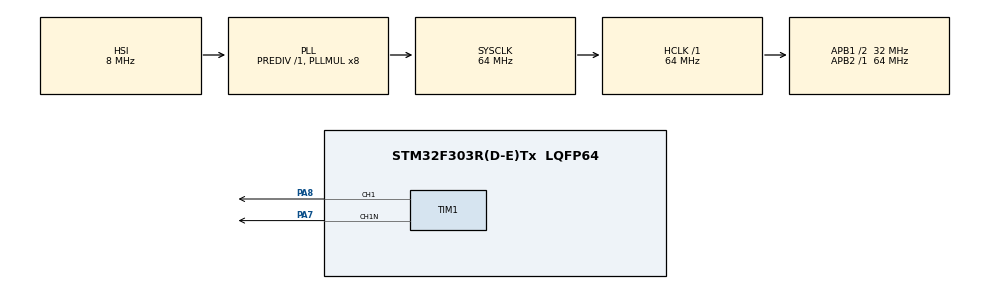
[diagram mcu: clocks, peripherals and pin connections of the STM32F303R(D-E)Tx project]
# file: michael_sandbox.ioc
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Mcu.Family=STM32F3
Mcu.Name=STM32F303R(D-E)Tx
Mcu.Package=LQFP64
NVIC.PriorityGroup=NVIC_PRIORITYGROUP_4
NVIC.TIM2_IRQn=true\:0\:0\:false\:false\:true\:true\:true
NVIC.TIM4_IRQn=true\:0\:0\:false\:false\:true\:true\:true
NVIC.TIM6_DAC_IRQn=true\:0\:0\:false\:false\:true\:true\:true
PA7.Mode=PWM Generation1 CH1 CH1N
PA7.Signal=TIM1_CH1N
PA8.Signal=S_TIM1_CH1
ProjectManager.HeapSize=0x200
ProjectManager.StackSize=0x400
ProjectManager.TargetToolchain=STM32CubeIDE
RCC.AHBFreq_Value=64000000
RCC.APB1CLKDivider=RCC_HCLK_DIV2
RCC.APB1Freq_Value=32000000
RCC.APB1TimFreq_Value=64000000
RCC.APB2Freq_Value=64000000
RCC.APB2TimFreq_Value=64000000
RCC.CortexFreq_Value=64000000
RCC.HCLKFreq_Value=64000000
RCC.HSE_VALUE=8000000
RCC.HSI_VALUE=8000000
RCC.LSE_VALUE=32768
RCC.PLLMUL=RCC_PLL_MUL8
RCC.SYSCLKFreq_VALUE=64000000
RCC.SYSCLKSourceVirtual=RCC_SYSCLKSOURCE_PLLCLK
RCC.USBFreq_Value=64000000
SH.S_TIM1_CH1.0=TIM1_CH1,PWM Generation1 CH1 CH1N
TIM1.Channel-PWM\ Generation1\ CH1\ CH1N=TIM_CHANNEL_1
TIM2.AutoReloadPreload=TIM_AUTORELOAD_PRELOAD_ENABLE
TIM2.CounterMode=TIM_COUNTERMODE_DOWN
TIM2.Period=6400
TIM4.AutoReloadPreload=TIM_AUTORELOAD_PRELOAD_ENABLE
TIM4.CounterMode=TIM_COUNTERMODE_DOWN
TIM4.Period=32000
TIM6.AutoReloadPreload=TIM_AUTORELOAD_PRELOAD_ENABLE
TIM6.Period=64
TIM6.Prescaler=10000
VP_TIM1_VS_ClockSourceINT.Mode=Internal
VP_TIM2_VS_ClockSourceINT.Mode=Internal
VP_TIM4_VS_ClockSourceINT.Mode=Internal
VP_TIM6_VS_ClockSourceINT.Mode=Enable_Timer
board=custom

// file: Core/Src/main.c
/* USER CODE BEGIN Header */
/**
  ******************************************************************************
  * @file           : main.c
  * @brief          : Main program body
  ******************************************************************************
  * @attention
  *
  * <h2><center>&copy; Copyright (c) 2019 STMicroelectronics.
  * All rights reserved.</center></h2>
  *
  * This software component is licensed by ST under BSD 3-Clause license,
  * the "License"; You may not use this file except in compliance with the
  * License. You may obtain a copy of the License at:
  *                        opensource.org/licenses/BSD-3-Clause
  *
  ******************************************************************************
  */
/* USER CODE END Header */

#include "main.h"

/* USER CODE BEGIN Includes */
#include "timer.h"
#include "gpio.h"
#include "fsm.h"

/* USER CODE END Includes */

TIM_HandleTypeDef htim1;
TIM_HandleTypeDef htim2;
TIM_HandleTypeDef htim4;
TIM_HandleTypeDef htim6;

/* USER CODE BEGIN PV */
fsm_t fsm;

/* USER CODE END PV */

void SystemClock_Config(void);
static void MX_GPIO_Init(void);
static void MX_TIM1_Init(void);
static void MX_TIM2_Init(void);
static void MX_TIM4_Init(void);
static void MX_TIM6_Init(void);

int main(void)
{

  /* MCU Configuration--------------------------------------------------------*/

  /* Reset of all peripherals, Initializes the Flash interface and the Systick. */
  HAL_Init();

  /* Configure the system clock */
  SystemClock_Config();

  /* Initialize all configured peripherals */
  MX_GPIO_Init();
  MX_TIM1_Init();
  MX_TIM2_Init();
  MX_TIM4_Init();
  MX_TIM6_Init();
  /* USER CODE BEGIN 2 */
  TIMxInit(TIM1);

  /* USER CODE END 2 */

  /* Infinite loop */
  while (1)
  {
	/* Sweep through duty cycles */

  }
}

void SystemClock_Config(void)
{
  RCC_OscInitTypeDef RCC_OscInitStruct = {0};
  RCC_ClkInitTypeDef RCC_ClkInitStruct = {0};
  RCC_PeriphCLKInitTypeDef PeriphClkInit = {0};

  /** Initializes the CPU, AHB and APB busses clocks
  */
  RCC_OscInitStruct.OscillatorType = RCC_OSCILLATORTYPE_HSI;
  RCC_OscInitStruct.HSIState = RCC_HSI_ON;
  RCC_OscInitStruct.HSICalibrationValue = RCC_HSICALIBRATION_DEFAULT;
  RCC_OscInitStruct.PLL.PLLState = RCC_PLL_ON;
  RCC_OscInitStruct.PLL.PLLSource = RCC_PLLSOURCE_HSI;
  RCC_OscInitStruct.PLL.PLLMUL = RCC_PLL_MUL8;
  RCC_OscInitStruct.PLL.PREDIV = RCC_PREDIV_DIV1;
  if (HAL_RCC_OscConfig(&RCC_OscInitStruct) != HAL_OK)
  {
    Error_Handler();
  }
  /** Initializes the CPU, AHB and APB busses clocks
  */
  RCC_ClkInitStruct.ClockType = RCC_CLOCKTYPE_HCLK|RCC_CLOCKTYPE_SYSCLK
                              |RCC_CLOCKTYPE_PCLK1|RCC_CLOCKTYPE_PCLK2;
  RCC_ClkInitStruct.SYSCLKSource = RCC_SYSCLKSOURCE_PLLCLK;
  RCC_ClkInitStruct.AHBCLKDivider = RCC_SYSCLK_DIV1;
  RCC_ClkInitStruct.APB1CLKDivider = RCC_HCLK_DIV2;
  RCC_ClkInitStruct.APB2CLKDivider = RCC_HCLK_DIV1;

  if (HAL_RCC_ClockConfig(&RCC_ClkInitStruct, FLASH_LATENCY_2) != HAL_OK)
  {
    Error_Handler();
  }
  PeriphClkInit.PeriphClockSelection = RCC_PERIPHCLK_TIM1|RCC_PERIPHCLK_TIM2
                              |RCC_PERIPHCLK_TIM34;
  PeriphClkInit.Tim1ClockSelection = RCC_TIM1CLK_HCLK;
  PeriphClkInit.Tim2ClockSelection = RCC_TIM2CLK_HCLK;
  PeriphClkInit.Tim34ClockSelection = RCC_TIM34CLK_HCLK;
  if (HAL_RCCEx_PeriphCLKConfig(&PeriphClkInit) != HAL_OK)
  {
    Error_Handler();
  }
}

static void MX_TIM1_Init(void)
{

  TIM_ClockConfigTypeDef sClockSourceConfig = {0};
  TIM_MasterConfigTypeDef sMasterConfig = {0};
  TIM_OC_InitTypeDef sConfigOC = {0};
  TIM_BreakDeadTimeConfigTypeDef sBreakDeadTimeConfig = {0};

  htim1.Instance = TIM1;
  htim1.Init.Prescaler = 0;
  htim1.Init.CounterMode = TIM_COUNTERMODE_UP;
  htim1.Init.Period = 0;
  htim1.Init.ClockDivision = TIM_CLOCKDIVISION_DIV1;
  htim1.Init.RepetitionCounter = 0;
  htim1.Init.AutoReloadPreload = TIM_AUTORELOAD_PRELOAD_DISABLE;
  if (HAL_TIM_Base_Init(&htim1) != HAL_OK)
  {
    Error_Handler();
  }
  sClockSourceConfig.ClockSource = TIM_CLOCKSOURCE_INTERNAL;
  if (HAL_TIM_ConfigClockSource(&htim1, &sClockSourceConfig) != HAL_OK)
  {
    Error_Handler();
  }
  if (HAL_TIM_PWM_Init(&htim1) != HAL_OK)
  {
    Error_Handler();
  }
  sMasterConfig.MasterOutputTrigger = TIM_TRGO_RESET;
  sMasterConfig.MasterOutputTrigger2 = TIM_TRGO2_RESET;
  sMasterConfig.MasterSlaveMode = TIM_MASTERSLAVEMODE_DISABLE;
  if (HAL_TIMEx_MasterConfigSynchronization(&htim1, &sMasterConfig) != HAL_OK)
  {
    Error_Handler();
  }
  sConfigOC.OCMode = TIM_OCMODE_PWM1;
  sConfigOC.Pulse = 0;
  sConfigOC.OCPolarity = TIM_OCPOLARITY_HIGH;
  sConfigOC.OCNPolarity = TIM_OCNPOLARITY_HIGH;
  sConfigOC.OCFastMode = TIM_OCFAST_DISABLE;
  sConfigOC.OCIdleState = TIM_OCIDLESTATE_RESET;
  sConfigOC.OCNIdleState = TIM_OCNIDLESTATE_RESET;
  if (HAL_TIM_PWM_ConfigChannel(&htim1, &sConfigOC, TIM_CHANNEL_1) != HAL_OK)
  {
    Error_Handler();
  }
  sBreakDeadTimeConfig.OffStateRunMode = TIM_OSSR_DISABLE;
  sBreakDeadTimeConfig.OffStateIDLEMode = TIM_OSSI_DISABLE;
  sBreakDeadTimeConfig.LockLevel = TIM_LOCKLEVEL_OFF;
  sBreakDeadTimeConfig.DeadTime = 0;
  sBreakDeadTimeConfig.BreakState = TIM_BREAK_DISABLE;
  sBreakDeadTimeConfig.BreakPolarity = TIM_BREAKPOLARITY_HIGH;
  sBreakDeadTimeConfig.BreakFilter = 0;
  sBreakDeadTimeConfig.Break2State = TIM_BREAK2_DISABLE;
  sBreakDeadTimeConfig.Break2Polarity = TIM_BREAK2POLARITY_HIGH;
  sBreakDeadTimeConfig.Break2Filter = 0;
  sBreakDeadTimeConfig.AutomaticOutput = TIM_AUTOMATICOUTPUT_DISABLE;
  if (HAL_TIMEx_ConfigBreakDeadTime(&htim1, &sBreakDeadTimeConfig) != HAL_OK)
  {
    Error_Handler();
  }
  HAL_TIM_MspPostInit(&htim1);

}

static void MX_TIM2_Init(void)
{

  TIM_ClockConfigTypeDef sClockSourceConfig = {0};
  TIM_MasterConfigTypeDef sMasterConfig = {0};

  htim2.Instance = TIM2;
  htim2.Init.Prescaler = 0;
  htim2.Init.CounterMode = TIM_COUNTERMODE_DOWN;
  htim2.Init.Period = 6400;
  htim2.Init.ClockDivision = TIM_CLOCKDIVISION_DIV1;
  htim2.Init.AutoReloadPreload = TIM_AUTORELOAD_PRELOAD_ENABLE;
  if (HAL_TIM_Base_Init(&htim2) != HAL_OK)
  {
    Error_Handler();
  }
  sClockSourceConfig.ClockSource = TIM_CLOCKSOURCE_INTERNAL;
  if (HAL_TIM_ConfigClockSource(&htim2, &sClockSourceConfig) != HAL_OK)
  {
    Error_Handler();
  }
  sMasterConfig.MasterOutputTrigger = TIM_TRGO_RESET;
  sMasterConfig.MasterSlaveMode = TIM_MASTERSLAVEMODE_DISABLE;
  if (HAL_TIMEx_MasterConfigSynchronization(&htim2, &sMasterConfig) != HAL_OK)
  {
    Error_Handler();
  }

}

static void MX_TIM4_Init(void)
{

  TIM_ClockConfigTypeDef sClockSourceConfig = {0};
  TIM_MasterConfigTypeDef sMasterConfig = {0};

  htim4.Instance = TIM4;
  htim4.Init.Prescaler = 0;
  htim4.Init.CounterMode = TIM_COUNTERMODE_DOWN;
  htim4.Init.Period = 32000;
  htim4.Init.ClockDivision = TIM_CLOCKDIVISION_DIV1;
  htim4.Init.AutoReloadPreload = TIM_AUTORELOAD_PRELOAD_ENABLE;
  if (HAL_TIM_Base_Init(&htim4) != HAL_OK)
  {
    Error_Handler();
  }
  sClockSourceConfig.ClockSource = TIM_CLOCKSOURCE_INTERNAL;
  if (HAL_TIM_ConfigClockSource(&htim4, &sClockSourceConfig) != HAL_OK)
  {
    Error_Handler();
  }
  sMasterConfig.MasterOutputTrigger = TIM_TRGO_RESET;
  sMasterConfig.MasterSlaveMode = TIM_MASTERSLAVEMODE_DISABLE;
  if (HAL_TIMEx_MasterConfigSynchronization(&htim4, &sMasterConfig) != HAL_OK)
  {
    Error_Handler();
  }

}

static void MX_TIM6_Init(void)
{

  TIM_MasterConfigTypeDef sMasterConfig = {0};

  htim6.Instance = TIM6;
  htim6.Init.Prescaler = 10000;
  htim6.Init.CounterMode = TIM_COUNTERMODE_UP;
  htim6.Init.Period = 64;
  htim6.Init.AutoReloadPreload = TIM_AUTORELOAD_PRELOAD_ENABLE;
  if (HAL_TIM_Base_Init(&htim6) != HAL_OK)
  {
    Error_Handler();
  }
  sMasterConfig.MasterOutputTrigger = TIM_TRGO_RESET;
  sMasterConfig.MasterSlaveMode = TIM_MASTERSLAVEMODE_DISABLE;
  if (HAL_TIMEx_MasterConfigSynchronization(&htim6, &sMasterConfig) != HAL_OK)
  {
    Error_Handler();
  }

}

static void MX_GPIO_Init(void)
{

  /* GPIO Ports Clock Enable */
  __HAL_RCC_GPIOA_CLK_ENABLE();

}

void Error_Handler(void)
{
}

/************************ (C) COPYRIGHT STMicroelectronics *****END OF FILE****/
